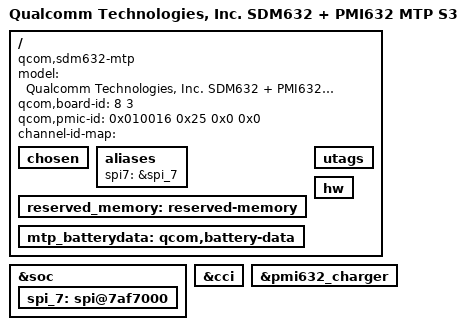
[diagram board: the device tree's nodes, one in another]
/* Copyright (c) 2018, The Linux Foundation. All rights reserved.
 *
 * This program is free software; you can redistribute it and/or modify
 * it under the terms of the GNU General Public License version 2 and
 * only version 2 as published by the Free Software Foundation.
 *
 * This program is distributed in the hope that it will be useful,
 * but WITHOUT ANY WARRANTY; without even the implied warranty of
 * MERCHANTABILITY or FITNESS FOR A PARTICULAR PURPOSE.  See the
 * GNU General Public License for more details.
 */

#include "sdm632.dtsi"
#include "sdm450-pmi632.dtsi"

&soc {
	spi_7: spi@7af7000 { };
};

/ {
/*
 * Some nodes need labels assigned to appear in __symbols__
 */
	model = "Qualcomm Technologies, Inc. SDM632 + PMI632 MTP S3";
	compatible = "qcom,sdm632-mtp", "qcom,sdm632", "qcom,mtp";
	qcom,board-id = <8 3>;
	qcom,pmic-id = <0x010016 0x25 0x0 0x0>;
	channel-id-map = "";

	chosen: chosen { };
	aliases: aliases {
		spi7 = &spi_7;
	};
	reserved_memory: reserved-memory { };
	mtp_batterydata: qcom,battery-data {};
	utags: utags { };
	hw: hw { };
};

&soc {
	/delete-node/ hbtp;
};
&cci {
	/delete-node/ qcom,actuator@0;
	/delete-node/ qcom,actuator@1;
	/delete-node/ qcom,eeprom@0;
	/delete-node/ qcom,eeprom@1;
	/delete-node/ qcom,eeprom@2;
	/delete-node/ qcom,camera@0;
	/delete-node/ qcom,camera@1;
	/delete-node/ qcom,camera@2;
};

&pmi632_charger {
	/delete-property/ qcom,sw-jeita-enable;
	/delete-property/ qcom,step-charging-enable;
	/delete-property/ qcom,hw-die-temp-mitigation;
	/delete-property/ qcom,hw-connector-mitigation;
};
